# ATxmega256A3BU device description
Architecture: AVR8_XMEGA; Family: AVR XMEGA
Registers are 8-bit, access not given, no defined reset value unless marked. A register's access mark holds for its fields unless they carry their own. Offsets are from the block's base; [hi:lo] are bit positions; {n}, {i} and the like mark numbered series; 'fields as' and 'values as' point back to an identical list.

## TC2 — 16-bit Timer/Counter type 2
Instances: TCC2 0x800, TCD2 0x900, TCE2 0xA00, TCF2 0xB00
0x00 CTRLA — Control Register A
  [3:0] CLKSEL — Clock Selection
    0=OFF (Timer Off); 1=DIV1 (System Clock); 2=DIV2 (System Clock / 2); 3=DIV4 (System Clock / 4); 4=DIV8 (System Clock / 8); 5=DIV64 (System Clock / 64); 6=DIV256 (System Clock / 256); 7=DIV1024 (System Clock / 1024); {v}=EVCH{v-8} (Event Channel {v-8}) (v=8..15)
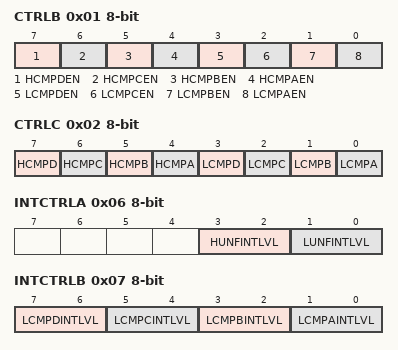
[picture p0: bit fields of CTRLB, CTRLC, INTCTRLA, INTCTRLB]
0x01 CTRLB — Control Register B
  [7] HCMPDEN — High Byte Compare D Enable
  [6] HCMPCEN — High Byte Compare C Enable
  [5] HCMPBEN — High Byte Compare B Enable
  [4] HCMPAEN — High Byte Compare A Enable
  [3] LCMPDEN — Low Byte Compare D Enable
  [2] LCMPCEN — Low Byte Compare C Enable
  [1] LCMPBEN — Low Byte Compare B Enable
  [0] LCMPAEN — Low Byte Compare A Enable
0x02 CTRLC — Control register C
  [7] HCMPD — High Byte Compare D Output Value
  [6] HCMPC — High Byte Compare C Output Value
  [5] HCMPB — High Byte Compare B Output Value
  [4] HCMPA — High Byte Compare A Output Value
  [3] LCMPD — Low Byte Compare D Output Value
  [2] LCMPC — Low Byte Compare C Output Value
  [1] LCMPB — Low Byte Compare B Output Value
  [0] LCMPA — Low Byte Compare A Output Value
0x04 CTRLE — Control Register E
  [1:0] BYTEM — Byte Mode
    0=NORMAL (16-bit mode); 1=BYTEMODE (Timer/Counter operating in byte mode only (TC2)); 2=SPLITMODE (Timer/Counter split into two 8-bit Counters)
0x06 INTCTRLA — Interrupt Control Register A
  [3:2] HUNFINTLVL — High Byte Underflow Interrupt Level
    0=OFF (Interrupt Disabled); 1=LO (Low Level); 2=MED (Medium Level); 3=HI (High Level)
  [1:0] LUNFINTLVL — Low Byte Underflow interrupt level
    values as HUNFINTLVL
0x07 INTCTRLB — Interrupt Control Register B
  [all] fields
    values as INTCTRLA.HUNFINTLVL
  [7:6] LCMPDINTLVL — Low Byte Compare D Interrupt Level
  [5:4] LCMPCINTLVL — Low Byte Compare C Interrupt Level
  [3:2] LCMPBINTLVL — Low Byte Compare B Interrupt Level
  [1:0] LCMPAINTLVL — Low Byte Compare A Interrupt Level
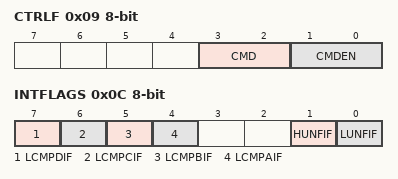
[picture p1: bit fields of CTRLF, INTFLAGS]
0x09 CTRLF — Control Register F
  [3:2] CMD — Command
    0=NONE (No Command); 2=RESTART (Force Restart); 3=RESET (Force Hard Reset)
  [1:0] CMDEN — Command Enable
    1=LOW (Low Byte Timer/Counter); 2=HIGH (High Byte Timer/Counter); 3=BOTH (Both Low Byte and High Byte Timer/Counters)
0x0C INTFLAGS — Interrupt Flag Register
  [7] LCMPDIF — Low Byte Compare D Interrupt Flag
  [6] LCMPCIF — Low Byte Compare C Interrupt Flag
  [5] LCMPBIF — Low Byte Compare B Interrupt Flag
  [4] LCMPAIF — Low Byte Compare A Interrupt Flag
  [1] HUNFIF — High Byte Underflow Interrupt Flag
  [0] LUNFIF — Low Byte Underflow Interrupt Flag
0x20 LCNT — Low Byte Count
0x21 HCNT — High Byte Count
0x26 LPER — Low Byte Period
0x27 HPER — High Byte Period
0x28 LCMPA — Low Byte Compare A
0x29 HCMPA — High Byte Compare A
0x2A LCMPB — Low Byte Compare B
0x2B HCMPB — High Byte Compare B
0x2C LCMPC — Low Byte Compare C
0x2D HCMPC — High Byte Compare C
0x2E LCMPD — Low Byte Compare D
0x2F HCMPD — High Byte Compare D

## AWEX — Advanced Waveform Extension
Instances: AWEXC 0x880, AWEXE 0xA80
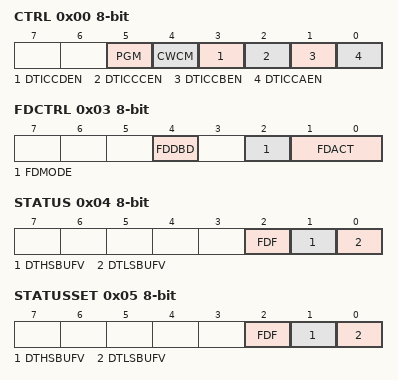
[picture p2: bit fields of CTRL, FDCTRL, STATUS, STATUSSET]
0x00 CTRL — Control Register
  [5] PGM — Pattern Generation Mode
  [4] CWCM — Common Waveform Channel Mode
  [3] DTICCDEN — Dead Time Insertion Compare Channel D Enable
  [2] DTICCCEN — Dead Time Insertion Compare Channel C Enable
  [1] DTICCBEN — Dead Time Insertion Compare Channel B Enable
  [0] DTICCAEN — Dead Time Insertion Compare Channel A Enable
0x02 FDEMASK — Fault Detection Event Mask
0x03 FDCTRL — Fault Detection Control Register
  [4] FDDBD — Fault Detect on Disable Break Disable
  [2] FDMODE — Fault Detect Mode
  [1:0] FDACT — Fault Detect Action
    0=NONE (No Fault Protection); 1=CLEAROE (Clear Output Enable Bits); 3=CLEARDIR (Clear I/O Port Direction Bits)
0x04 STATUS
  [2] FDF — Fault Detect Flag
  [1] DTHSBUFV — Dead Time High Side Buffer Valid
  [0] DTLSBUFV — Dead Time Low Side Buffer Valid
0x05 STATUSSET
  fields as STATUS
0x06 DTBOTH — Dead Time Both Sides
0x07 DTBOTHBUF — Dead Time Both Sides Buffer
0x08 DTLS — Dead Time Low Side
0x09 DTHS — Dead Time High Side
0x0A DTLSBUF — Dead Time Low Side Buffer
0x0B DTHSBUF — Dead Time High Side Buffer
0x0C OUTOVEN — Output Override Enable
